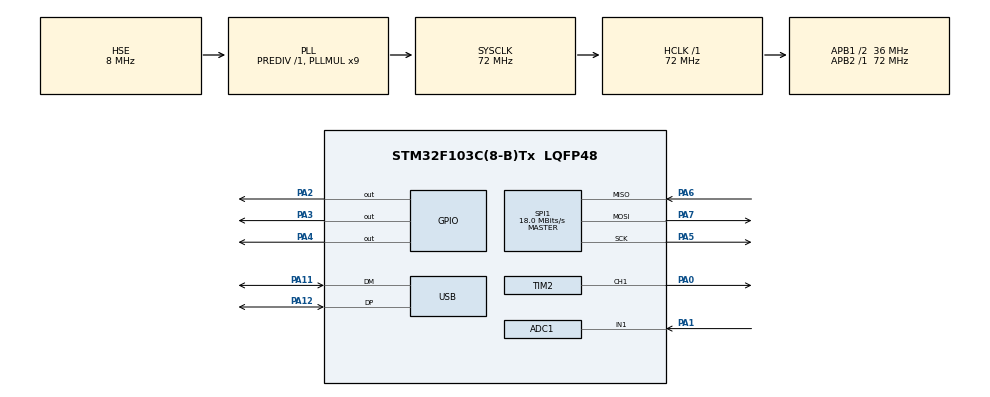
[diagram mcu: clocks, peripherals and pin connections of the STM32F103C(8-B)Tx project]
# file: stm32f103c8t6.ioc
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ADC1.Channel-8\#ChannelRegularConversion=ADC_CHANNEL_1
ADC1.NbrOfConversionFlag=1
ADC1.Rank-8\#ChannelRegularConversion=1
ADC1.SamplingTime-8\#ChannelRegularConversion=ADC_SAMPLETIME_1CYCLE_5
ADC1.master=1
Dma.Request0=SPI1_RX
Dma.Request1=SPI1_TX
Dma.SPI1_RX.0.Direction=DMA_PERIPH_TO_MEMORY
Dma.SPI1_RX.0.Instance=DMA1_Channel2
Dma.SPI1_RX.0.MemDataAlignment=DMA_MDATAALIGN_BYTE
Dma.SPI1_RX.0.MemInc=DMA_MINC_ENABLE
Dma.SPI1_RX.0.Mode=DMA_NORMAL
Dma.SPI1_RX.0.PeriphDataAlignment=DMA_PDATAALIGN_BYTE
Dma.SPI1_RX.0.PeriphInc=DMA_PINC_DISABLE
Dma.SPI1_RX.0.Priority=DMA_PRIORITY_LOW
Dma.SPI1_TX.1.Direction=DMA_MEMORY_TO_PERIPH
Dma.SPI1_TX.1.Instance=DMA1_Channel3
Dma.SPI1_TX.1.MemDataAlignment=DMA_MDATAALIGN_BYTE
Dma.SPI1_TX.1.MemInc=DMA_MINC_ENABLE
Dma.SPI1_TX.1.Mode=DMA_NORMAL
Dma.SPI1_TX.1.PeriphDataAlignment=DMA_PDATAALIGN_BYTE
Dma.SPI1_TX.1.PeriphInc=DMA_PINC_DISABLE
Dma.SPI1_TX.1.Priority=DMA_PRIORITY_LOW
Mcu.Family=STM32F1
Mcu.Name=STM32F103C(8-B)Tx
Mcu.Package=LQFP48
NVIC.DMA1_Channel2_IRQn=true\:0\:0\:false\:false\:true
NVIC.DMA1_Channel3_IRQn=true\:0\:0\:false\:false\:true
NVIC.PriorityGroup=NVIC_PRIORITYGROUP_4
NVIC.SPI1_IRQn=true\:0\:0\:false\:false\:true
NVIC.TIM3_IRQn=true\:0\:0\:false\:false\:true
NVIC.TIM4_IRQn=true\:0\:0\:false\:false\:true
NVIC.USB_LP_CAN1_RX0_IRQn=true\:0\:0\:false\:false\:true
PA0-WKUP.GPIO_Speed=GPIO_SPEED_FREQ_HIGH
PA0-WKUP.Signal=S_TIM2_CH1_ETR
PA1.Signal=ADCx_IN1
PA11.Mode=Device
PA11.Signal=USB_DM
PA12.Mode=Device
PA12.Signal=USB_DP
PA13.Mode=Serial_Wire
PA13.Signal=SYS_JTMS-SWDIO
PA14.Mode=Serial_Wire
PA14.Signal=SYS_JTCK-SWCLK
PA2.Signal=GPIO_Output
PA3.Signal=GPIO_Output
PA4.GPIO_Speed=GPIO_SPEED_FREQ_MEDIUM
PA4.PinState=GPIO_PIN_RESET
PA4.Signal=GPIO_Output
PA5.Mode=Full_Duplex_Master
PA5.Signal=SPI1_SCK
PA6.Mode=Full_Duplex_Master
PA6.Signal=SPI1_MISO
PA7.Mode=Full_Duplex_Master
PA7.Signal=SPI1_MOSI
PD0-OSC_IN.Mode=HSE-External-Oscillator
PD0-OSC_IN.Signal=RCC_OSC_IN
PD1-OSC_OUT.Mode=HSE-External-Oscillator
PD1-OSC_OUT.Signal=RCC_OSC_OUT
ProjectManager.HeapSize=0x200
ProjectManager.StackSize=0x400
ProjectManager.TargetToolchain=SW4STM32
RCC.ADCPresc=RCC_ADCPCLK2_DIV6
RCC.AHBFreq_Value=72000000
RCC.APB1CLKDivider=RCC_HCLK_DIV2
RCC.APB1Freq_Value=36000000
RCC.APB1TimFreq_Value=72000000
RCC.APB2Freq_Value=72000000
RCC.APB2TimFreq_Value=72000000
RCC.HCLKFreq_Value=72000000
RCC.PLLMUL=RCC_PLL_MUL9
RCC.PLLSourceVirtual=RCC_PLLSOURCE_HSE
RCC.SYSCLKFreq_VALUE=72000000
RCC.SYSCLKSource=RCC_SYSCLKSOURCE_PLLCLK
RCC.USBFreq_Value=48000000
RCC.USBPrescaler=RCC_USBCLKSOURCE_PLL_DIV1_5
SH.ADCx_IN1.0=ADC1_IN1,IN1
SH.S_TIM2_CH1_ETR.0=TIM2_CH1,PWM Generation1 CH1
SPI1.BaudRatePrescaler=SPI_BAUDRATEPRESCALER_4
SPI1.CalculateBaudRate=18.0 MBits/s
SPI1.Direction=SPI_DIRECTION_2LINES
SPI1.Mode=SPI_MODE_MASTER
SPI1.VirtualType=VM_MASTER
TIM2.Channel-PWM\ Generation1\ CH1=TIM_CHANNEL_1
TIM2.Period=1880-1
TIM2.Pulse-PWM\ Generation1\ CH1=940
TIM3.Period=(500-1)
TIM3.Prescaler=(72-1)
TIM3.TIM_MasterOutputTrigger=TIM_TRGO_UPDATE
TIM3.TIM_MasterSlaveMode=TIM_MASTERSLAVEMODE_DISABLE
TIM4.Period=(1880-1)
TIM4.Prescaler=0
TIM4.TIM_MasterOutputTrigger=TIM_TRGO_OC1
USB_DEVICE.CLASS_NAME_FS=CDC
USB_DEVICE.MANUFACTURER_STRING=AuvirTech
USB_DEVICE.VirtualMode=Cdc
USB_DEVICE.VirtualModeFS=Cdc_FS
VP_CRC_VS_CRC.Mode=CRC_Activate
VP_TIM2_VS_ClockSourceINT.Mode=Internal
VP_TIM3_VS_ClockSourceINT.Mode=Internal
VP_TIM4_VS_ClockSourceINT.Mode=Internal
VP_USB_DEVICE_VS_USB_DEVICE_CDC_FS.Mode=CDC_FS
board=stm32f103c8t6

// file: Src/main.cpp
/**
  ******************************************************************************
  * File Name          : main.c
  * Description        : Main program body
  ******************************************************************************
  * This notice applies to any and all portions of this file
  * that are not between comment pairs USER CODE BEGIN and
  * USER CODE END. Other portions of this file, whether
  * inserted by the user or by software development tools
  * are owned by their respective copyright owners.
  *
  * Copyright (c) 2017 STMicroelectronics International N.V.
  * All rights reserved.
  *
  * Redistribution and use in source and binary forms, with or without
  * modification, are permitted, provided that the following conditions are met:
  *
  * 1. Redistribution of source code must retain the above copyright notice,
  *    this list of conditions and the following disclaimer.
  * 2. Redistributions in binary form must reproduce the above copyright notice,
  *    this list of conditions and the following disclaimer in the documentation
  *    and/or other materials provided with the distribution.
  * 3. Neither the name of STMicroelectronics nor the names of other
  *    contributors to this software may be used to endorse or promote products
  *    derived from this software without specific written permission.
  * 4. This software, including modifications and/or derivative works of this
  *    software, must execute solely and exclusively on microcontroller or
  *    microprocessor devices manufactured by or for STMicroelectronics.
  * 5. Redistribution and use of this software other than as permitted under
  *    this license is void and will automatically terminate your rights under
  *    this license.
  *
  * THIS SOFTWARE IS PROVIDED BY STMICROELECTRONICS AND CONTRIBUTORS "AS IS"
  * AND ANY EXPRESS, IMPLIED OR STATUTORY WARRANTIES, INCLUDING, BUT NOT
  * LIMITED TO, THE IMPLIED WARRANTIES OF MERCHANTABILITY, FITNESS FOR A
  * PARTICULAR PURPOSE AND NON-INFRINGEMENT OF THIRD PARTY INTELLECTUAL PROPERTY
  * RIGHTS ARE DISCLAIMED TO THE FULLEST EXTENT PERMITTED BY LAW. IN NO EVENT
  * SHALL STMICROELECTRONICS OR CONTRIBUTORS BE LIABLE FOR ANY DIRECT, INDIRECT,
  * INCIDENTAL, SPECIAL, EXEMPLARY, OR CONSEQUENTIAL DAMAGES (INCLUDING, BUT NOT
  * LIMITED TO, PROCUREMENT OF SUBSTITUTE GOODS OR SERVICES; LOSS OF USE, DATA,
  * OR PROFITS; OR BUSINESS INTERRUPTION) HOWEVER CAUSED AND ON ANY THEORY OF
  * LIABILITY, WHETHER IN CONTRACT, STRICT LIABILITY, OR TORT (INCLUDING
  * NEGLIGENCE OR OTHERWISE) ARISING IN ANY WAY OUT OF THE USE OF THIS SOFTWARE,
  * EVEN IF ADVISED OF THE POSSIBILITY OF SUCH DAMAGE.
  *
  ******************************************************************************
  */
#include "main.h"
#include "stm32f1xx_hal.h"
#include "usb_device.h"

/* USER CODE BEGIN Includes */
#include "infrared.h"
#include "se8r01.h"
#include <stdbool.h>

#define USE_OLD_MAPPING 1
#include "common.h"

/* USER CODE END Includes */

ADC_HandleTypeDef hadc1;

CRC_HandleTypeDef hcrc;

SPI_HandleTypeDef hspi1;
DMA_HandleTypeDef hdma_spi1_rx;
DMA_HandleTypeDef hdma_spi1_tx;

extern "C" {
extern TIM_HandleTypeDef htim2;
extern TIM_HandleTypeDef htim3;
extern TIM_HandleTypeDef htim4;
}

extern "C" {
uint8_t CDC_Transmit_FS(uint8_t *Buf, uint16_t Len);
}

/* USER CODE BEGIN PV */
/* Private variables ---------------------------------------------------------*/

// TODO: cleanup when done debugging
namespace auvir {
const bool _debug = true;
const uint32_t pwm_tim_channel = TIM_CHANNEL_1;
extern TIM_HandleTypeDef *const phtim_envelop;
extern TIM_HandleTypeDef *const phtim_pwm;
extern TIM_HandleTypeDef *const phtim_delay;
}

/// interface with radio
extern NRF_Module default_module;
extern NRF_Module data_module;

extern RadioMessage tx_message;
extern RadioDevInfo radiodevinfo;
extern SensorData sensordata;

/* USER CODE END PV */

void SystemClock_Config(void);
static void MX_GPIO_Init(void);
static void MX_DMA_Init(void);
static void MX_CRC_Init(void);
static void MX_SPI1_Init(void);
static void MX_TIM3_Init(void);
static void MX_TIM4_Init(void);
static void MX_TIM2_Init(void);
static void MX_ADC1_Init(void);

void HAL_TIM_MspPostInit(TIM_HandleTypeDef *htim);

/* USER CODE BEGIN PFP */
/* Private function prototypes -----------------------------------------------*/
void IR_TIM_Init(TIM_HandleTypeDef *p_envelop, TIM_HandleTypeDef *p_pwm);

void test_stuff();

bool is_usb_configured();

void configure_usb();

void configure_gpio_shiftreg();
void shiftreg_send_16bit_data(uint16_t data);
void shiftreg_send_8bit_data(uint8_t data);

/* USER CODE END PFP */

/* USER CODE BEGIN 0 */
#ifdef __cplusplus
extern "C" {
#endif
const NRF24_Mode mode = NRF24_Mode::Receiver;
#ifdef __cplusplus
}
#endif

void pwm() {
  HAL_Init();
  SystemClock_Config();

  __HAL_RCC_GPIOA_CLK_ENABLE();

  /// Init PWM timer
  TIM_ClockConfigTypeDef sClockSourceConfig;
  TIM_MasterConfigTypeDef sMasterConfig;
  TIM_OC_InitTypeDef sConfigOC;

  htim2.Instance = TIM2;
  htim2.Init.Prescaler = 72; // 0; //TODO: return to 0
  htim2.Init.CounterMode = TIM_COUNTERMODE_UP;
  htim2.Init.Period = 1000;
  htim2.Init.ClockDivision = TIM_CLOCKDIVISION_DIV1;
  if (HAL_TIM_Base_Init(&htim2) != HAL_OK) {
    _Error_Handler(__FILE__, __LINE__);
  }

  sClockSourceConfig.ClockSource = TIM_CLOCKSOURCE_INTERNAL;
  if (HAL_TIM_ConfigClockSource(&htim2, &sClockSourceConfig) != HAL_OK) {
    _Error_Handler(__FILE__, __LINE__);
  }

  if (HAL_TIM_PWM_Init(&htim2) != HAL_OK) {
    _Error_Handler(__FILE__, __LINE__);
  }

  sMasterConfig.MasterOutputTrigger = TIM_TRGO_RESET;
  sMasterConfig.MasterSlaveMode = TIM_MASTERSLAVEMODE_DISABLE;
  if (HAL_TIMEx_MasterConfigSynchronization(&htim2, &sMasterConfig) != HAL_OK) {
    _Error_Handler(__FILE__, __LINE__);
  }

  sConfigOC.OCMode = TIM_OCMODE_PWM1;
  sConfigOC.Pulse = 300;
  sConfigOC.OCPolarity = TIM_OCPOLARITY_HIGH;
  sConfigOC.OCFastMode = TIM_OCFAST_DISABLE;
  if (HAL_TIM_PWM_ConfigChannel(&htim2, &sConfigOC, TIM_CHANNEL_1) != HAL_OK) {
    _Error_Handler(__FILE__, __LINE__);
  }

  HAL_TIM_MspPostInit(&htim2);
  HAL_TIM_PWM_Start(auvir::phtim_pwm, TIM_CHANNEL_1);

  ///
  while (1) {
  }
}

/* USER CODE END 0 */

int main(void) {
  /* USER CODE BEGIN 1 */

  // for uploading to separate mc which lights up LED with PWM
  pwm();

  /* USER CODE END 1 */

  /* MCU
   * Configuration----------------------------------------------------------*/

  /* Reset of all peripherals, Initializes the Flash interface and the Systick.
   */
  HAL_Init();

  /* Configure the system clock */
  SystemClock_Config();

  /* Initialize all configured peripherals */
  MX_GPIO_Init();
  MX_DMA_Init();
  MX_CRC_Init();
  MX_SPI1_Init();
  MX_TIM3_Init();
  MX_TIM4_Init();
  MX_TIM2_Init();
  MX_ADC1_Init();
  MX_USB_DEVICE_Init();

  /* USER CODE BEGIN 2 */
  configure_usb();

  HAL_ADCEx_Calibration_Start(&hadc1);

  // TODO fix IR_TIM_Init function
  /// IR_TIM_Init(phtim_envelop, phtim_pwm);
  // init_beamer_channels_gpio();

  /*Configure GPIO pin Output Level */
  bool use_shiftreg = false;
  if (use_shiftreg) {
    configure_gpio_shiftreg();
  }

  bool use_radio = false;
  if (use_radio) {
    configure_gpio_radio();
    setup_radio(&default_module, mode);
  }
  // envelop
  /// HAL_TIM_Base_Start_IT(phtim_envelop);

  // pwm
  /// HAL_TIM_PWM_Start(auvir::phtim_pwm, TIM_CHANNEL_1);

  // TODO: this is requred. Refactor to avoid possible mistakes in the future
  // start usec delay timer
  HAL_TIM_Base_Start(auvir::phtim_delay);
  // TODO: make more clean TODOs in the future. What the heck is required?!

  /* USER CODE END 2 */

  /* Infinite loop */
  /* USER CODE BEGIN WHILE */
  // prepare buffer for sending over USB
  const char *helloworld_str = "hello world!\n";

  uint32_t adc_values[1000] = {0};

  while (1) {
    // test_stuff();

    for (int i = 0; i < 1000; ++i) {
      HAL_ADC_Start(&hadc1);
      while (HAL_ADC_PollForConversion(&hadc1, 10)) {
      }
      adc_values[i] = HAL_ADC_GetValue(&hadc1);
      HAL_ADC_Stop(&hadc1);

      // TODO: check if casting below depend on endiannes
      // adc_val = 1234;
      /// uint8_t *curr_adc_val_buf = reinterpret_cast<uint8_t
      /// *>(&adc_values[i]);
      /// uint32_t restored_adc_val = 0;
      /// restored_adc_val = (curr_adc_val_buf[3] << 24) |
      ///                   (curr_adc_val_buf[2] << 16) |
      ///                   (curr_adc_val_buf[1] << 8) | (curr_adc_val_buf[0]);
    }

    /// HAL_GPIO_TogglePin(LED_ONBOARD_Port, LED_ONBOARD_Pin);

    // CDC_Transmit_FS(&size, 1);
    CDC_Transmit_FS(reinterpret_cast<uint8_t *>(adc_values),
                    sizeof(uint32_t) * 1000);

    // CDC_Transmit_FS((uint8_t *)helloworld_str, strlen(helloworld_str));

    /* USER CODE END WHILE */

  }
}

/** System Clock Configuration
*/
void SystemClock_Config(void) {
  RCC_OscInitTypeDef RCC_OscInitStruct;
  RCC_ClkInitTypeDef RCC_ClkInitStruct;
  RCC_PeriphCLKInitTypeDef PeriphClkInit;

  /**Initializes the CPU, AHB and APB busses clocks
  */
  RCC_OscInitStruct.OscillatorType = RCC_OSCILLATORTYPE_HSE;
  RCC_OscInitStruct.HSEState = RCC_HSE_ON;
  RCC_OscInitStruct.HSEPredivValue = RCC_HSE_PREDIV_DIV1;
  RCC_OscInitStruct.HSIState = RCC_HSI_ON;
  RCC_OscInitStruct.PLL.PLLState = RCC_PLL_ON;
  RCC_OscInitStruct.PLL.PLLSource = RCC_PLLSOURCE_HSE;
  RCC_OscInitStruct.PLL.PLLMUL = RCC_PLL_MUL9;
  if (HAL_RCC_OscConfig(&RCC_OscInitStruct) != HAL_OK) {
    _Error_Handler(__FILE__, __LINE__);
  }

  /**Initializes the CPU, AHB and APB busses clocks
  */
  RCC_ClkInitStruct.ClockType = RCC_CLOCKTYPE_HCLK | RCC_CLOCKTYPE_SYSCLK |
                                RCC_CLOCKTYPE_PCLK1 | RCC_CLOCKTYPE_PCLK2;
  RCC_ClkInitStruct.SYSCLKSource = RCC_SYSCLKSOURCE_PLLCLK;
  RCC_ClkInitStruct.AHBCLKDivider = RCC_SYSCLK_DIV1;
  RCC_ClkInitStruct.APB1CLKDivider = RCC_HCLK_DIV2;
  RCC_ClkInitStruct.APB2CLKDivider = RCC_HCLK_DIV1;

  if (HAL_RCC_ClockConfig(&RCC_ClkInitStruct, FLASH_LATENCY_2) != HAL_OK) {
    _Error_Handler(__FILE__, __LINE__);
  }

  PeriphClkInit.PeriphClockSelection = RCC_PERIPHCLK_ADC | RCC_PERIPHCLK_USB;
  PeriphClkInit.AdcClockSelection = RCC_ADCPCLK2_DIV6;
  PeriphClkInit.UsbClockSelection = RCC_USBCLKSOURCE_PLL_DIV1_5;
  if (HAL_RCCEx_PeriphCLKConfig(&PeriphClkInit) != HAL_OK) {
    _Error_Handler(__FILE__, __LINE__);
  }

  /**Configure the Systick interrupt time
  */
  HAL_SYSTICK_Config(HAL_RCC_GetHCLKFreq() / 1000);

  /**Configure the Systick
  */
  HAL_SYSTICK_CLKSourceConfig(SYSTICK_CLKSOURCE_HCLK);

  /* SysTick_IRQn interrupt configuration */
  HAL_NVIC_SetPriority(SysTick_IRQn, 0, 0);
}

/* ADC1 init function */
static void MX_ADC1_Init(void) {
  ADC_ChannelConfTypeDef sConfig;

  /**Common config
  */
  hadc1.Instance = ADC1;
  hadc1.Init.ScanConvMode = ADC_SCAN_DISABLE;
  hadc1.Init.ContinuousConvMode = DISABLE;
  hadc1.Init.DiscontinuousConvMode = DISABLE;
  hadc1.Init.ExternalTrigConv = ADC_SOFTWARE_START;
  hadc1.Init.DataAlign = ADC_DATAALIGN_RIGHT;
  hadc1.Init.NbrOfConversion = 1;
  if (HAL_ADC_Init(&hadc1) != HAL_OK) {
    _Error_Handler(__FILE__, __LINE__);
  }

  /**Configure Regular Channel
  */
  sConfig.Channel = ADC_CHANNEL_1;
  sConfig.Rank = 1;
  sConfig.SamplingTime = ADC_SAMPLETIME_1CYCLE_5;
  if (HAL_ADC_ConfigChannel(&hadc1, &sConfig) != HAL_OK) {
    _Error_Handler(__FILE__, __LINE__);
  }
}

/* CRC init function */
static void MX_CRC_Init(void) {
  hcrc.Instance = CRC;
  if (HAL_CRC_Init(&hcrc) != HAL_OK) {
    _Error_Handler(__FILE__, __LINE__);
  }
}

/* SPI1 init function */
static void MX_SPI1_Init(void) {
  hspi1.Instance = SPI1;
  hspi1.Init.Mode = SPI_MODE_MASTER;
  hspi1.Init.Direction = SPI_DIRECTION_2LINES;
  hspi1.Init.DataSize = SPI_DATASIZE_8BIT;
  hspi1.Init.CLKPolarity = SPI_POLARITY_LOW;
  hspi1.Init.CLKPhase = SPI_PHASE_1EDGE;
  hspi1.Init.NSS = SPI_NSS_SOFT;
  hspi1.Init.BaudRatePrescaler = SPI_BAUDRATEPRESCALER_4;
  hspi1.Init.FirstBit = SPI_FIRSTBIT_MSB;
  hspi1.Init.TIMode = SPI_TIMODE_DISABLE;
  hspi1.Init.CRCCalculation = SPI_CRCCALCULATION_DISABLE;
  hspi1.Init.CRCPolynomial = 10;
  if (HAL_SPI_Init(&hspi1) != HAL_OK) {
    _Error_Handler(__FILE__, __LINE__);
  }
}

/* TIM2 init function */
static void MX_TIM2_Init(void) {
  TIM_ClockConfigTypeDef sClockSourceConfig;
  TIM_MasterConfigTypeDef sMasterConfig;
  TIM_OC_InitTypeDef sConfigOC;

  htim2.Instance = TIM2;
  htim2.Init.Prescaler = 720; // 0; //TODO: return to 0
  htim2.Init.CounterMode = TIM_COUNTERMODE_UP;
  htim2.Init.Period = 1880 - 1;
  htim2.Init.ClockDivision = TIM_CLOCKDIVISION_DIV1;
  if (HAL_TIM_Base_Init(&htim2) != HAL_OK) {
    _Error_Handler(__FILE__, __LINE__);
  }

  sClockSourceConfig.ClockSource = TIM_CLOCKSOURCE_INTERNAL;
  if (HAL_TIM_ConfigClockSource(&htim2, &sClockSourceConfig) != HAL_OK) {
    _Error_Handler(__FILE__, __LINE__);
  }

  if (HAL_TIM_PWM_Init(&htim2) != HAL_OK) {
    _Error_Handler(__FILE__, __LINE__);
  }

  sMasterConfig.MasterOutputTrigger = TIM_TRGO_RESET;
  sMasterConfig.MasterSlaveMode = TIM_MASTERSLAVEMODE_DISABLE;
  if (HAL_TIMEx_MasterConfigSynchronization(&htim2, &sMasterConfig) != HAL_OK) {
    _Error_Handler(__FILE__, __LINE__);
  }

  sConfigOC.OCMode = TIM_OCMODE_PWM1;
  sConfigOC.Pulse = 940;
  sConfigOC.OCPolarity = TIM_OCPOLARITY_HIGH;
  sConfigOC.OCFastMode = TIM_OCFAST_DISABLE;
  if (HAL_TIM_PWM_ConfigChannel(&htim2, &sConfigOC, TIM_CHANNEL_1) != HAL_OK) {
    _Error_Handler(__FILE__, __LINE__);
  }

  HAL_TIM_MspPostInit(&htim2);
}

/* TIM3 init function */
static void MX_TIM3_Init(void) {
  TIM_ClockConfigTypeDef sClockSourceConfig;
  TIM_MasterConfigTypeDef sMasterConfig;

  htim3.Instance = TIM3;
  htim3.Init.Prescaler = (72 - 1);
  htim3.Init.CounterMode = TIM_COUNTERMODE_UP;
  htim3.Init.Period = (500 - 1);
  htim3.Init.ClockDivision = TIM_CLOCKDIVISION_DIV1;
  if (HAL_TIM_Base_Init(&htim3) != HAL_OK) {
    _Error_Handler(__FILE__, __LINE__);
  }

  sClockSourceConfig.ClockSource = TIM_CLOCKSOURCE_INTERNAL;
  if (HAL_TIM_ConfigClockSource(&htim3, &sClockSourceConfig) != HAL_OK) {
    _Error_Handler(__FILE__, __LINE__);
  }

  sMasterConfig.MasterOutputTrigger = TIM_TRGO_UPDATE;
  sMasterConfig.MasterSlaveMode = TIM_MASTERSLAVEMODE_DISABLE;
  if (HAL_TIMEx_MasterConfigSynchronization(&htim3, &sMasterConfig) != HAL_OK) {
    _Error_Handler(__FILE__, __LINE__);
  }
}

/* TIM4 init function */
static void MX_TIM4_Init(void) {
  TIM_ClockConfigTypeDef sClockSourceConfig;
  TIM_MasterConfigTypeDef sMasterConfig;

  htim4.Instance = TIM4;
  htim4.Init.Prescaler = 0;
  htim4.Init.CounterMode = TIM_COUNTERMODE_UP;
  htim4.Init.Period = (1880 - 1);
  htim4.Init.ClockDivision = TIM_CLOCKDIVISION_DIV1;
  if (HAL_TIM_Base_Init(&htim4) != HAL_OK) {
    _Error_Handler(__FILE__, __LINE__);
  }

  sClockSourceConfig.ClockSource = TIM_CLOCKSOURCE_INTERNAL;
  if (HAL_TIM_ConfigClockSource(&htim4, &sClockSourceConfig) != HAL_OK) {
    _Error_Handler(__FILE__, __LINE__);
  }

  sMasterConfig.MasterOutputTrigger = TIM_TRGO_OC1;
  sMasterConfig.MasterSlaveMode = TIM_MASTERSLAVEMODE_DISABLE;
  if (HAL_TIMEx_MasterConfigSynchronization(&htim4, &sMasterConfig) != HAL_OK) {
    _Error_Handler(__FILE__, __LINE__);
  }
}

static void MX_DMA_Init(void) {
  /* DMA controller clock enable */
  __HAL_RCC_DMA1_CLK_ENABLE();

  /* DMA interrupt init */
  /* DMA1_Channel2_IRQn interrupt configuration */
  HAL_NVIC_SetPriority(DMA1_Channel2_IRQn, 0, 0);
  HAL_NVIC_EnableIRQ(DMA1_Channel2_IRQn);
  /* DMA1_Channel3_IRQn interrupt configuration */
  HAL_NVIC_SetPriority(DMA1_Channel3_IRQn, 0, 0);
  HAL_NVIC_EnableIRQ(DMA1_Channel3_IRQn);
}

/** Configure pins as
        * Analog
        * Input
        * Output
        * EVENT_OUT
        * EXTI
*/
static void MX_GPIO_Init(void) {
  GPIO_InitTypeDef GPIO_InitStruct;

  /* GPIO Ports Clock Enable */
  __HAL_RCC_GPIOD_CLK_ENABLE();
  __HAL_RCC_GPIOA_CLK_ENABLE();
  __HAL_RCC_GPIOC_CLK_ENABLE();

  /*Configure GPIO pin Output Level */
  HAL_GPIO_WritePin(GPIOA, GPIO_PIN_2 | GPIO_PIN_3 | GPIO_PIN_4,
                    GPIO_PIN_RESET);

  /*Configure GPIO pins : PA2 PA3 */
  GPIO_InitStruct.Pin = GPIO_PIN_2 | GPIO_PIN_3;
  GPIO_InitStruct.Mode = GPIO_MODE_OUTPUT_PP;
  GPIO_InitStruct.Speed = GPIO_SPEED_FREQ_LOW;
  HAL_GPIO_Init(GPIOA, &GPIO_InitStruct);

  /*Configure GPIO pin : PA4 */
  GPIO_InitStruct.Pin = GPIO_PIN_4;
  GPIO_InitStruct.Mode = GPIO_MODE_OUTPUT_PP;
  GPIO_InitStruct.Speed = GPIO_SPEED_FREQ_MEDIUM;
  HAL_GPIO_Init(GPIOA, &GPIO_InitStruct);

  /*Configure GPIO pins for LED */
  GPIO_InitStruct.Pin = LED_ONBOARD_Pin;
  GPIO_InitStruct.Mode = GPIO_MODE_OUTPUT_PP;
  GPIO_InitStruct.Speed = GPIO_SPEED_FREQ_LOW;
  HAL_GPIO_Init(LED_ONBOARD_Port, &GPIO_InitStruct);
}

/* USER CODE BEGIN 4 */

void IR_TIM_Init(TIM_HandleTypeDef *p_envelop, TIM_HandleTypeDef *p_pwm) {
  p_envelop->Init.Period = pwm_timer_period;
  HAL_TIM_Base_Init(p_envelop);

  p_pwm->Init.Prescaler = envelop_timer_prescaler;
  p_pwm->Init.Period = DataBitLength;
  HAL_TIM_Base_Init(p_pwm);
}

void test_stuff() {
  uint8_t led8_array[8] = {
      0b00000001, // 1
      0b00000010, // 2
      0b00000100, // 3
      0b00001000, // 4
      0b00010000, // 5
      0b00100000, // 6
      0b01000000, // 7
      0b10000000, // 8
  };
  uint16_t led16_array[16] = {
      0b0000000000000001, // 1
      0b0000000000000010, // 2
      0b0000000000000100, // 3
      0b0000000000001000, // 4
      0b0000000000010000, // 5
      0b0000000000100000, // 6
      0b0000000001000000, // 7
      0b0000000010000000, // 8
      0b0000000100000000, // 9
      0b0000001000000000, // 10
      0b0000010000000000, // 11
      0b0000100000000000, // 12
      0b0001000000000000, // 13
      0b0010000000000000, // 14
      0b0100000000000000, // 15
      0b1000000000000000, // 16
  };
  uint16_t led16_array_tmp[8] = {
      0b1010101010101010, // 1
      0b1001001001001001, // 2
      0b1000100010001000, // 3
      0b1000010000100001, // 4
      0b0000000000010000, // 5
      0b0000000000100000, // 6
      0b0000000001000000, // 7
      0b0000000010000000, // 8
  };
  uint8_t led_num = 0;
  uint16_t test_msg = 0b1010101010101010;

  /*
  /// check SPI module by reading status register from radio module
  uint8_t s_reg = iRF_BANK0_STATUS;
  uint8_t S = 0;
  HAL_GPIO_WritePin(NRF24_CSN1_Port, NRF24_CSN1_Pin, GPIO_PIN_RESET);
  // CSN low,
  initialize SPI communication...
  HAL_SPI_TransmitReceive_IT(&hspi1, &s_reg, &S, 1);
  uint8_t reg_val = HAL_SPI_TransmitReceive_IT(&hspi1, 0, &S, 1);
  HAL_GPIO_WritePin(NRF24_CSN1_Port, NRF24_CSN1_Pin, GPIO_PIN_SET);          //
  CSN
  high, terminate SPI communication
    */

  /// test spi for shift register
  /// shiftreg_send_16bit_data(test_msg);
  /// HAL_Delay(10);

  /*
if(use_shiftreg)
  {
    if(led_num == 16)
      led_num = 0;
    else
      led_num++;
      shiftreg_send_16bit_data(led16_array[led_num]);
  }
  */
  for (int i = 0; i < 16; ++i) {
    shiftreg_send_16bit_data(led16_array[i]);
    HAL_Delay(10);
  }

/*
if(is_receiver && false){
    RXX(&default_module);// - this is called on IRQ
}
else{
      //=================== prepare message for sending
      // Determine source of packet
      radio_tx_set_message_header(WhoAmI_Beamer, Dest_Sensor, Typ_SensorData);

      BeamerData beamerdata;
      SingleBeamerData data;
      data.angle = 10;
      data.beamer_id = 12;
      for(int i = 0; i < MAX_BEAMERS_PER_SENSOR; ++i ){
          beamerdata.beamer_data_array[i] = data;
      }

      sensordata.sensor_id = data.beamer_id;
      set_sensordata_type (&sensordata, SDT_BeamerData);
      set_sensor_data_beamer (&sensordata, &beamerdata);

      radio_tx_set_sensordata(&sensordata);
      //=====================

      HAL_Delay (1000);
    TXX(&default_module);
}
*/

#if 0 // TODO
init_data();
sensor_send_data();
#endif
}

bool is_usb_configured() {
  if (&hUsbDeviceFS == NULL) {
    return false;
  }
  if (hUsbDeviceFS.dev_state != USBD_STATE_CONFIGURED) {
    return false;
  }
  return true;
}

void configure_usb() {
  // TODO: read more on this process of configuring
  while (!is_usb_configured()) {
    // NOP
  };
}

void TIM2_Init_pprev(void) {
  TIM_ClockConfigTypeDef sClockSourceConfig;
  TIM_MasterConfigTypeDef sMasterConfig;

  htim2.Instance = TIM2;
  htim2.Init.Prescaler = 0;
  htim2.Init.CounterMode = TIM_COUNTERMODE_UP;
  htim2.Init.Period = 0;
  htim2.Init.ClockDivision = TIM_CLOCKDIVISION_DIV1;
  HAL_TIM_Base_Init(&htim2);

  sClockSourceConfig.ClockSource = TIM_CLOCKSOURCE_INTERNAL;
  HAL_TIM_ConfigClockSource(&htim2, &sClockSourceConfig);

  sMasterConfig.MasterOutputTrigger = TIM_TRGO_RESET;
  sMasterConfig.MasterSlaveMode = TIM_MASTERSLAVEMODE_DISABLE;
  HAL_TIMEx_MasterConfigSynchronization(&htim2, &sMasterConfig);
}

void TIM3_Init_prev(void) {
  TIM_ClockConfigTypeDef sClockSourceConfig;
  TIM_MasterConfigTypeDef sMasterConfig;

  htim3.Instance = TIM3;
  htim3.Init.Prescaler = (72 - 1);
  htim3.Init.CounterMode = TIM_COUNTERMODE_UP;
  htim3.Init.Period = (500 - 1);
  htim3.Init.ClockDivision = TIM_CLOCKDIVISION_DIV1;
  HAL_TIM_Base_Init(&htim3);

  sClockSourceConfig.ClockSource = TIM_CLOCKSOURCE_INTERNAL;
  HAL_TIM_ConfigClockSource(&htim3, &sClockSourceConfig);

  sMasterConfig.MasterOutputTrigger = TIM_TRGO_UPDATE;
  sMasterConfig.MasterSlaveMode = TIM_MASTERSLAVEMODE_DISABLE;
  HAL_TIMEx_MasterConfigSynchronization(&htim3, &sMasterConfig);
}

void TIM4_Init_prev(void) {
  TIM_ClockConfigTypeDef sClockSourceConfig;
  TIM_MasterConfigTypeDef sMasterConfig;
  TIM_OC_InitTypeDef sConfigOC;

  htim4.Instance = TIM4;
  htim4.Init.Prescaler = 0;
  htim4.Init.CounterMode = TIM_COUNTERMODE_UP;
  htim4.Init.Period = (1880 - 1);
  htim4.Init.ClockDivision = TIM_CLOCKDIVISION_DIV1;
  HAL_TIM_Base_Init(&htim4);

  sClockSourceConfig.ClockSource = TIM_CLOCKSOURCE_INTERNAL;
  HAL_TIM_ConfigClockSource(&htim4, &sClockSourceConfig);

  HAL_TIM_PWM_Init(&htim4);

  sMasterConfig.MasterOutputTrigger = TIM_TRGO_OC1;
  sMasterConfig.MasterSlaveMode = TIM_MASTERSLAVEMODE_DISABLE;
  HAL_TIMEx_MasterConfigSynchronization(&htim4, &sMasterConfig);

  sConfigOC.OCMode = TIM_OCMODE_PWM1;
  sConfigOC.Pulse = (940 - 1);
  sConfigOC.OCPolarity = TIM_OCPOLARITY_HIGH;
  sConfigOC.OCFastMode = TIM_OCFAST_DISABLE;
  HAL_TIM_PWM_ConfigChannel(&htim4, &sConfigOC, TIM_CHANNEL_4);

  HAL_TIM_MspPostInit(&htim4);
}

/* USER CODE END 4 */

extern "C" {
void _Error_Handler(const char *file, int line) {
  while (1) {
  }
}
}

#ifdef USE_FULL_ASSERT

/**
   * @brief Reports the name of the source file and the source line number
   * where the assert_param error has occurred.
   * @param file: pointer to the source file name
   * @param line: assert_param error line source number
   * @retval None
   */
void assert_failed(uint8_t *file, uint32_t line) {
  /* USER CODE BEGIN 6 */
  /* User can add his own implementation to report the file name and line
    number,
    ex: printf("Wrong parameters value: file %s on line %d\r\n", file, line) */
  /* USER CODE END 6 */
}

#endif

/************************ (C) COPYRIGHT STMicroelectronics *****END OF FILE****/
